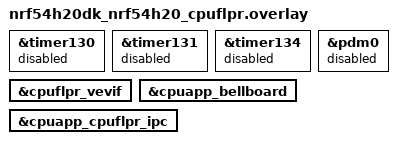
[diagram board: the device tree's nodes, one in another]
/*
 * Copyright (c) 2026 Nordic Semiconductor ASA
 *
 * SPDX-License-Identifier: Apache-2.0
 */

dut_timer0: &timer130 {
	status = "reserved";
};

dut_timer1: &timer131 {
	status = "reserved";
};

dut_timer2: &timer134 {
	status = "reserved";
};

&pdm0 {
	status = "reserved";
};

&cpuflpr_vevif {
	status = "okay";
};

&cpuapp_bellboard {
	status = "okay";
};

ipc0: &cpuapp_cpuflpr_ipc {
	status = "okay";
};
